# MK52DZ10 register map
Vendor: Freescale Semiconductor, Inc.; Series: Kinetis_K; File version: 1.6
CPU: CM4 r0p1, little endian, no MPU, no FPU, VTOR, 4 interrupt priority bits
Registers are 32-bit, read-write, reset 0x0 unless marked. A register's access mark holds for its fields unless they carry their own. Offsets are from the block's base; [hi:lo] are bit positions; {n}, {i} and the like mark numbered series.

## OPAMP0 — General Purpose Operational Amplifier
Base 0x400F5000; register names take the prefix OPAMP0_
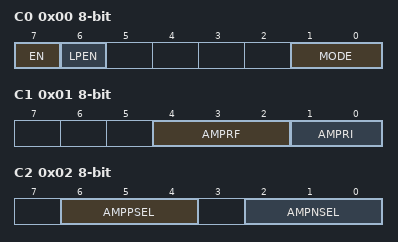
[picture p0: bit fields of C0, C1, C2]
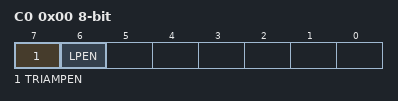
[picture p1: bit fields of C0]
0x00 C0 8-bit — Control Register 0
  [7] EN — OPAMP Enable
    0=OPAMP is disabled and not powered; 1=OPAMP is enabled and powered
  [6] LPEN — Low-Power Mode Enable
    0=High-speed mode selected. In this mode, OPAMP has faster slew rate and unity gain bandwidth performance with higher current consumption.; 1=Low-power mode selected. In this mode, OPAMP has lower current consumption with slower slew rate and unity gain bandwidth performance.
  [1:0] MODE — OPAMP Mode Select
    0=Buffer; 2=General purpose; 1=Inverting PGA; 3=Non-inverting PGA
0x01 C1 8-bit — Control Register 1
  [4:2] AMPRF — Gains Selector
  [1:0] AMPRI — Gains Selector
0x02 C2 8-bit — Control Register 2
  [6:4] AMPPSEL — Amplifier Positive Input Terminal Selector
    {v}=Positive input {v} (v=0..7)
  [2:0] AMPNSEL — Amplifier Negative Input Terminal Selector.
    {v}=Negative input {v} (v=0..7)

## OPAMP1 — General Purpose Operational Amplifier
Base 0x400F5800; register names take the prefix OPAMP1_
Registers as OPAMP0.

## TRIAMP0 — Trans-Impedance Amplifier
Base 0x400F8000; register names take the prefix TRIAMP0_
0x00 C0 8-bit — Control Register 0
  [7] TRIAMPEN — TRIAMP Enable
    0=The amplifier is disabled and not powered; 1=TRIAMP system is enabled. In this mode the amplifier is powered and enabled.
  [6] LPEN — Low-Power Enable
    0=High-speed mode selected. In this mode, TRIAMP has faster slew rate and unity gain bandwidth performance with higher current consumption.; 1=Low-power mode selected. In this mode, TRIAMP has lower current consumption with slower slew rate and unity gain bandwidth performance.

## TRIAMP1 — Trans-Impedance Amplifier
Base 0x400F8800; register names take the prefix TRIAMP1_
Registers as TRIAMP0.

## PTA — General Purpose Input/Output
Base 0x400FF000; register names take the prefix GPIOA_
0x00 PDOR — Port Data Output Register
  [31:0] PDO — Port Data Output
    0=Logic level 0 is driven on pin provided pin is configured for General Purpose Output; 1=Logic level 1 is driven on pin provided pin is configured for General Purpose Output
0x04 PSOR wo — Port Set Output Register
  [31:0] PTSO — Port Set Output
    0=Corresponding bit in PDORn does not change; 1=Corresponding bit in PDORn is set to logic one
0x08 PCOR wo — Port Clear Output Register
  [31:0] PTCO — Port Clear Output
    0=Corresponding bit in PDORn does not change; 1=Corresponding bit in PDORn is set to logic zero
0x0C PTOR wo — Port Toggle Output Register
  [31:0] PTTO — Port Toggle Output
    0=Corresponding bit in PDORn does not change; 1=Corresponding bit in PDORn is set to the inverse of its existing logic state
0x10 PDIR ro — Port Data Input Register
  [31:0] PDI — Port Data Input
    0=Pin logic level is logic zero or is configured for use by digital function; 1=Pin logic level is logic one
0x14 PDDR — Port Data Direction Register
  [31:0] PDD — Port data direction
    0=Pin is configured as general purpose input, if configured for the GPIO function; 1=Pin is configured for general purpose output, if configured for the GPIO function

## PTB — General Purpose Input/Output
Base 0x400FF040; register names take the prefix GPIOB_
Registers as PTA.

## PTC — General Purpose Input/Output
Base 0x400FF080; register names take the prefix GPIOC_
Registers as PTA; these are added or differ:
0x08 PCOR wo — Port Clear Output Register
  [31:0] PTCO — Port Clear Output
    0=Corresponding bit in PDORn does not change; 1=Corresponding bit in PDORn is set to logic zero

## PTD — General Purpose Input/Output
Base 0x400FF0C0; register names take the prefix GPIOD_
Registers as PTA.

## PTE — General Purpose Input/Output
Base 0x400FF100; register names take the prefix GPIOE_
Registers as PTA.

## Notices in the file
Redistribution and use in source and binary forms, with or without modification,
are permitted provided that the following conditions are met:
o Redistributions of source code must retain the above copyright notice, this list
of conditions and the following disclaimer.
o Redistributions in binary form must reproduce the above copyright notice, this
list of conditions and the following disclaimer in the documentation and/or
other materials provided with the distribution.
o Neither the name of Freescale Semiconductor, Inc. nor the names of its
contributors may be used to endorse or promote products derived from this
software without specific prior written permission.
THIS SOFTWARE IS PROVIDED BY THE COPYRIGHT HOLDERS AND CONTRIBUTORS "AS IS" AND
ANY EXPRESS OR IMPLIED WARRANTIES, INCLUDING, BUT NOT LIMITED TO, THE IMPLIED
WARRANTIES OF MERCHANTABILITY AND FITNESS FOR A PARTICULAR PURPOSE ARE
DISCLAIMED. IN NO EVENT SHALL THE COPYRIGHT HOLDER OR CONTRIBUTORS BE LIABLE FOR
ANY DIRECT, INDIRECT, INCIDENTAL, SPECIAL, EXEMPLARY, OR CONSEQUENTIAL DAMAGES
(INCLUDING, BUT NOT LIMITED TO, PROCUREMENT OF SUBSTITUTE GOODS OR SERVICES;
LOSS OF USE, DATA, OR PROFITS; OR BUSINESS INTERRUPTION) HOWEVER CAUSED AND ON
ANY THEORY OF LIABILITY, WHETHER IN CONTRACT, STRICT LIABILITY, OR TORT
(INCLUDING NEGLIGENCE OR OTHERWISE) ARISING IN ANY WAY OUT OF THE USE OF THIS
SOFTWARE, EVEN IF ADVISED OF THE POSSIBILITY OF SUCH DAMAGE.
